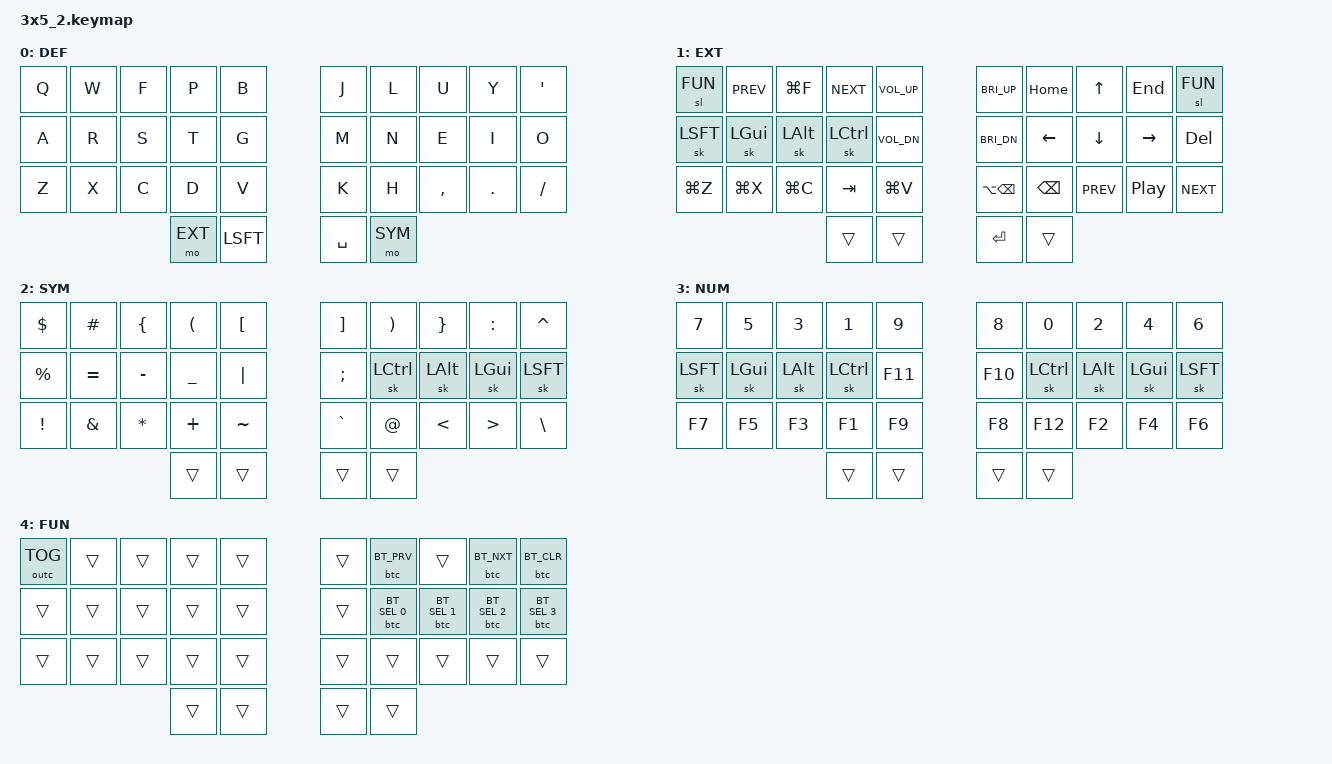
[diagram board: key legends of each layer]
/*
* Copyright (c) 2021 Sviatoslav Bulbakha
 *
 * SPDX-License-Identifier: MIT
 */

#define DEF 0
#define EXT 1
#define SYM 2
#define NUM 3
#define FUN 4

#define ALL DEF EXT SYM NUM FUN

#include <behaviors.dtsi>
#include <dt-bindings/zmk/keys.h>
#include <dt-bindings/zmk/bt.h>
#include <dt-bindings/zmk/ext_power.h>
#include <dt-bindings/zmk/outputs.h>

#define PREV LC(LS(TAB))
#define NEXT LC(TAB)

  /* ╭────────────────────┬────────────────────╮ */
  /* │  0   1   2   3   4 │  5   6   7   8   9 │ */
  /* │ 10  11  12  13  14 │ 15  16  17  18  19 │ */
  /* │ 20  21  22  23  24 │ 25  26  27  28  29 │ */
  /* ╰───────────╮ 30  31 │ 32  33 ╭───────────╯ */
  /*             ╰────────┴────────╯ */

#define COMBO(NAME, BINDINGS, KEYPOS, LAYERS, TERM) \
  combo_##NAME { \
    timeout-ms = <TERM>; \
    bindings = <BINDINGS>; \
    key-positions = <KEYPOS>; \
    layers = <LAYERS>; \
  };

&sk {
  release-after-ms = <1000>;
  quick-release;
  no-sticky-after-hold-ms = <500>; // requires PR #1788
};

&caps_word {
  mods = <(MOD_RSFT)>;
  /delete-property/ ignore-modifiers; // requires PR #1451
};

/ {
  conditional_layers {
    compatible = "zmk,conditional-layers";

    fun_tri_layer {
      if-layers = <1 2>;
      then-layer = <3>;
    };
  };

  behaviors {
    smart_shift: smart_shift {
      compatible = "zmk,behavior-mod-morph";
      #binding-cells = <0>;
      bindings = <&sk RSFT>, <&caps_word>;
      mods = <(MOD_RSFT)>;
    };
  };

  macros {
    you: you {
      compatible = "zmk,behavior-macro";
      #binding-cells = <0>;
      bindings = <&macro_tap &kp Y &kp O &kp U>;
    };

    btc: btc {
      compatible = "zmk,behavior-macro-two-param";
      #binding-cells = <2>;
      bindings = <&macro_param_1to1>, <&macro_param_2to2>, <&bt MACRO_PLACEHOLDER MACRO_PLACEHOLDER>, <&kp K_CANCEL>;
    };

    outc: outc {
      compatible = "zmk,behavior-macro-one-param";
      #binding-cells = <1>;
      bindings = <&macro_param_1to1>, <&out MACRO_PLACEHOLDER>, <&kp K_CANCEL>;
    };
  };

  combos {
    compatible = "zmk,combos";

    COMBO(esc, &kp ESC, 1 3, ALL, 60)
    COMBO(mute, &kp C_MUTE, 4 14, EXT, 50)
  };

  keymap {
    compatible = "zmk,keymap";

    def_layer {
      label = "DEF";
      bindings = <
      &kp Q        &kp W        &kp F        &kp P        &kp B          &kp J        &kp L        &kp U        &kp Y        &kp SQT
      &kp A        &kp R        &kp S        &kp T        &kp G          &kp M        &kp N        &kp E        &kp I        &kp O
      &kp Z        &kp X        &kp C        &kp D        &kp V          &kp K        &kp H        &kp COMMA    &kp DOT      &kp FSLH
                                             &mo EXT      &kp LSFT        &kp SPC      &mo SYM
      >;
    };

    ext_layer {
      label = "EXT";
      bindings = <
      &sl FUN      &kp PREV     &kp LG(F)     &kp NEXT     &kp C_VOL_UP  &kp C_BRI_UP &kp HOME     &kp UP       &kp END      &sl FUN
      &sk LSFT     &sk LGUI     &sk LALT      &sk LCTL     &kp C_VOL_DN  &kp C_BRI_DN &kp LEFT     &kp DOWN     &kp RIGHT    &kp DEL
      &kp LG(Z)    &kp LG(X)    &kp LG(C)     &kp TAB      &kp LG(V)     &kp LA(BSPC) &kp BSPC     &kp C_PREV   &kp C_PP     &kp C_NEXT
                                              &trans       &trans        &kp RET       &trans
      >;
    };

    sym_layer {
      label = "SYM";
      bindings = <
      &kp DLLR     &kp HASH     &kp LBRC      &kp LPAR     &kp LBKT      &kp RBKT     &kp RPAR     &kp RBRC     &kp COLON    &kp CARET
      &kp PRCNT    &kp EQUAL    &kp MINUS     &kp UNDER    &kp PIPE      &kp SEMI     &sk LCTL     &sk LALT     &sk LGUI     &sk LSFT
      &kp EXCL     &kp AMPS     &kp STAR      &kp PLUS     &kp TILDE     &kp GRAVE    &kp AT       &kp LT       &kp GT       &kp BSLH
                                              &trans       &trans       &trans       &trans
      >;
    };

    num_layer {
      label = "NUM";
      bindings = <
      &kp N7       &kp N5       &kp N3        &kp N1       &kp N9        &kp N8       &kp N0       &kp N2       &kp N4       &kp N6
      &sk LSFT     &sk LGUI     &sk LALT      &sk LCTL     &kp F11       &kp F10      &sk LCTL     &sk LALT     &sk LGUI     &sk LSFT
      &kp F7       &kp F5       &kp F3        &kp F1       &kp F9        &kp F8       &kp F12      &kp F2       &kp F4       &kp F6
                                              &trans       &trans        &trans       &trans
      >;
    };

    fun_layer {
      label = "FUN";
      bindings = <
      &outc OUT_TOG &trans      &trans       &trans       &trans         &trans       &btc BT_PRV  &trans       &btc BT_NXT &btc BT_CLR

      &trans       &trans       &trans       &trans       &trans         &trans       &btc BT_SEL 0  &btc BT_SEL 1  &btc BT_SEL 2       &btc BT_SEL 3
      &trans       &trans       &trans       &trans       &trans         &trans       &trans       &trans       &trans       &trans
      &trans       &trans         &trans       &trans
      >;
    };
  };
};
